# PIC16F18877 register map
File version: 1.0
PIC16F18877 special function registers
Registers are 8-bit, read-write, reset 0x0 unless marked. A register's access mark holds for its fields unless they carry their own. Offsets are from the block's base; lines under a group give offsets from that group; [hi:lo] are bit positions; {n}, {i} and the like mark numbered series; 'fields as' and 'values as' point back to an identical list; <NAME> marks a mode.

## Memory map
0x00800000 CPU size 0x1FF0 — Core registers
0x0080000C PORTA size 0x1F34
0x0080000D PORTB size 0x1F3E
0x0080000E PORTC size 0x1F48
0x0080000F PORTD size 0x1F4F
0x00800010 PORTE size 0x1F5C
0x0080001C TIMER0 size 0x4
0x0080008C ADC size 0x1E38 — Analog-to-digital converter
0x0080008E OTHER size 0x1EE0 — Other registers
0x00800119 EUSART size 0x7
0x0080018C MSSP size 0x1D3F — Synchronous serial port
0x0080020C TIMER1 size 0x6
0x00800212 TIMER3 size 0x6
0x00800218 TIMER5 size 0x6
0x0080021E CCP size 0x1C88 — Capture, compare and PWM
0x0080028E TIMER2 size 0x4
0x00800294 TIMER4 size 0x4
0x0080029A TIMER6 size 0x4
0x0080070C INTERRUPTS size 0x13 — Interrupt flags and enables
0x00800796 NVM size 0x8A — Flash and EEPROM access
0x0080080C SYSTEM size 0x8 — Reset, watchdog and pin options
0x0080088D OSCILLATOR size 0xA
0x0080090C REFERENCES size 0x4 — Voltage reference, DAC and SR latch
0x0080098F COMPARATORS size 0x9
0x00801E8F PPS size 0xA4 — Peripheral pin select

## CPU — Core registers
Base 0x00800000
0x00 INDF0 reset not defined — INDF0, data address 0x000
0x01 INDF1 reset not defined — INDF1, data address 0x001
0x02 PCL — PCL, data address 0x002
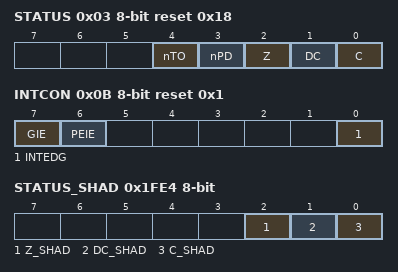
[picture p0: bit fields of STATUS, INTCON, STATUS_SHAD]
0x03 STATUS reset 0x18 — STATUS, data address 0x003
  [4] nTO, [3] nPD, [2] Z, [1] DC, [0] C
0x04 FSR0L — FSR0L, data address 0x004
0x05 FSR0H — FSR0H, data address 0x005
0x06 FSR1L — FSR1L, data address 0x006
0x07 FSR1H — FSR1H, data address 0x007
0x08 BSR — BSR, data address 0x008
  [5:0] BSR
0x09 WREG — WREG, data address 0x009
  [7:0] WREG0
0x0A PCLATH — PCLATH, data address 0x00a
  [6:0] PCLATH
0x0B INTCON reset 0x1 — INTCON, data address 0x00b
  [7] GIE, [6] PEIE, [0] INTEDG
0x1FE4 STATUS_SHAD reset not defined — STATUS_SHAD, data address 0x1fe4
  [2] Z_SHAD, [1] DC_SHAD, [0] C_SHAD
0x1FE5 WREG_SHAD reset not defined — WREG_SHAD, data address 0x1fe5
0x1FE6 BSR_SHAD reset not defined — BSR_SHAD, data address 0x1fe6
  [5:0] BSR_SHAD
0x1FE7 PCLATH_SHAD reset not defined — PCLATH_SHAD, data address 0x1fe7
  [6:0] PCLATH_SHAD
0x1FE8 FSR0L_SHAD reset not defined — FSR0L_SHAD, data address 0x1fe8
0x1FE9 FSR0H_SHAD reset not defined — FSR0H_SHAD, data address 0x1fe9
0x1FEA FSR1L_SHAD reset not defined — FSR1L_SHAD, data address 0x1fea
0x1FEB FSR1H_SHAD reset not defined — FSR1H_SHAD, data address 0x1feb
0x1FED STKPTR reset 0x1F — STKPTR, data address 0x1fed
  [4:0] STKPTR
0x1FEE TOSL reset not defined — TOSL, data address 0x1fee
0x1FEF TOSH reset not defined — TOSH, data address 0x1fef
  [6:0] TOSH

## ADC — Analog-to-digital converter
Base 0x0080008C
0x00 ADRESL — ADRESL, data address 0x08c
0x01 ADRESH — ADRESH, data address 0x08d
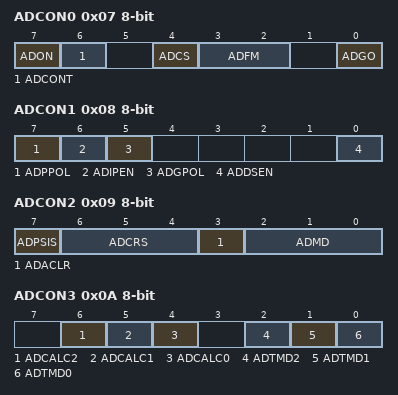
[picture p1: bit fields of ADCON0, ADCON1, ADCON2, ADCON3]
0x07 ADCON0 (reset mask 0xD5) — ADCON0, data address 0x093
  [7] ADON, [6] ADCONT, [4] ADCS, [3:2] ADFM, [0] ADGO
0x08 ADCON1 — ADCON1, data address 0x094
  [7] ADPPOL, [6] ADIPEN, [5] ADGPOL, [0] ADDSEN
0x09 ADCON2 — ADCON2, data address 0x095
  [7] ADPSIS, [6:4] ADCRS, [3] ADACLR, [2:0] ADMD
0x0A ADCON3 — ADCON3, data address 0x096
  [6] ADCALC2, [5] ADCALC1, [4] ADCALC0, [2] ADTMD2, [1] ADTMD1, [0] ADTMD0
0x0C ADCLK — ADCLK, data address 0x098
  [5:0] ADCCS
0x0D ADACT — ADACT, data address 0x099
  [4:0] ADACT
0x0F ADCAP — ADCAP, data address 0x09b
  [4:0] ADCAP
0x80 ADCNT reset not defined — ADCNT, data address 0x10c
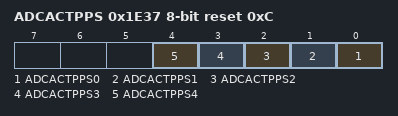
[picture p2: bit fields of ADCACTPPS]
0x1E37 ADCACTPPS reset 0xC — ADCACTPPS, data address 0x1ec3
  [n] ADCACTPPS{n} (n=0..4)

## CCP — Capture, compare and PWM
Base 0x0080021E
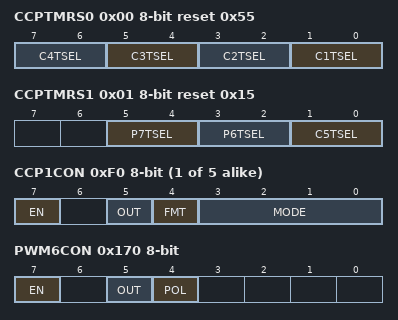
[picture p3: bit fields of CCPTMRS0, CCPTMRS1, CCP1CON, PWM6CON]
0x00 CCPTMRS0 reset 0x55 — CCPTMRS0, data address 0x21e
  [2n-1:2n-2] C{n}TSEL (n=1..4)
0x01 CCPTMRS1 reset 0x15 — CCPTMRS1, data address 0x21f
  [5:4] P7TSEL, [3:2] P6TSEL, [1:0] C5TSEL
{0xEA+4i} CCPR{i}L reset not defined (i=1..5) — CCPR{i}L, data address {0x308+4i}
  [7:0] RL
{0xEB+4i} CCPR{i}H reset not defined (i=1..5) — CCPR{i}H, data address {0x309+4i}
  [7:0] RH
{0xEC+4i} CCP{i}CON (i=1..5) — CCP{i}CON, data address {0x30A+4i}
  [7] EN, [5] OUT, [4] FMT, [3:0] MODE
{0xED+4i} CCP{i}CAP (reset mask 0x7) (i=1..5) — CCP{i}CAP, data address {0x30B+4i}
  [7:0] CTS
0x16E PWM6DCL reset not defined — PWM6DCL, data address 0x38c
  [7:6] DC
0x16F PWM6DCH reset not defined — PWM6DCH, data address 0x38d
  [7:0] DC
0x170 PWM6CON — PWM6CON, data address 0x38e
  [7] EN, [5] OUT, [4] POL
0x172 PWM7DCL reset not defined — PWM7DCL, data address 0x390
  [7:6] DC
0x173 PWM7DCH reset not defined — PWM7DCH, data address 0x391
  [7:0] DC
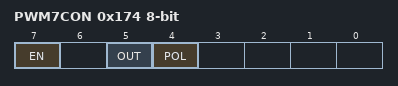
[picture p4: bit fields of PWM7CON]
0x174 PWM7CON — PWM7CON, data address 0x392
  [7] EN, [5] OUT, [4] POL
0x1C83 CCP1PPS reset 0x12 — CCP1PPS, data address 0x1ea1
  [4:0] CCP1PPS
0x1C84 CCP2PPS reset 0x11 — CCP2PPS, data address 0x1ea2
  [4:0] CCP2PPS
0x1C85 CCP3PPS reset 0xD — CCP3PPS, data address 0x1ea3
  [4:0] CCP3PPS
0x1C86 CCP4PPS reset 0x8 — CCP4PPS, data address 0x1ea4
  [4:0] CCP4PPS
0x1C87 CCP5PPS reset 0x4 — CCP5PPS, data address 0x1ea5
  [5:0] CCP5PPS
